VERSION ""

NS_ :

BS_:

BU_:

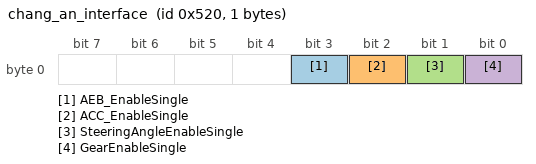
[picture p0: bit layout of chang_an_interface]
BO_ 1312 chang_an_interface: 1 Vector__XXX
 SG_ AEB_EnableSingle : 3|1@1+ (1,0) [0|1] "1" Vector__XXX
 SG_ ACC_EnableSingle : 2|1@1+ (1,0) [0|1] "" Vector__XXX
 SG_ SteeringAngleEnableSingle : 1|1@1+ (1,0) [0|1] "" Vector__XXX
 SG_ GearEnableSingle : 0|1@1+ (1,0) [0|1] "" Vector__XXX

BA_DEF_  "DBName" STRING ;
BA_DEF_  "Baud Rate" INT 0 100000;
BA_DEF_  "BusType" STRING ;
BA_DEF_DEF_  "DBName" "";
BA_DEF_DEF_  "Baud Rate" 20;
BA_DEF_DEF_  "BusType" "FlexRay";
BA_ "DBName" "MPC574x";
